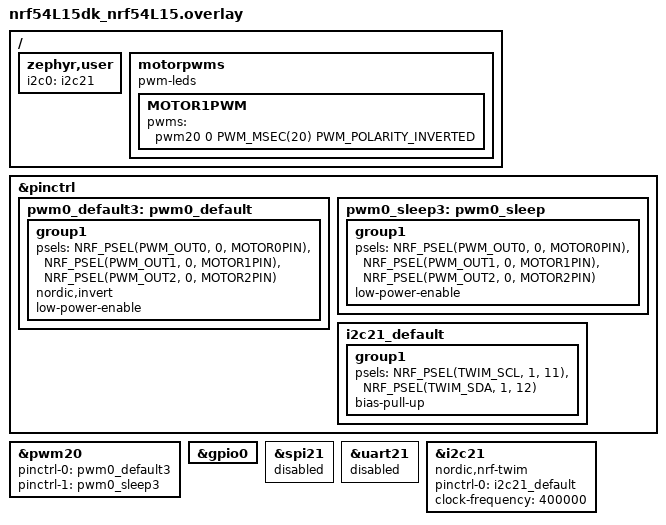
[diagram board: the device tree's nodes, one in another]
// To get started, press Ctrl+Space to bring up the completion menu and view the available nodes.

// You can also use the buttons in the sidebar to perform actions on nodes.
// Actions currently available include:

// * Enabling / disabling the node
// * Adding the bus to a bus
// * Removing the node
// * Connecting ADC channels

// For more help, browse the DeviceTree documentation at https://docs.zephyrproject.org/latest/guides/dts/index.html
// You can also visit the nRF DeviceTree extension documentation at https://nrfconnect.github.io/vscode-nrf-connect/devicetree/nrfdevicetree.html
/* old notation: 
&pwm0 {
    status = "okay";
    ch1-pin = <15>;
    /delete-property/ ch1-inverted;
}; */

#define MOTOR0PIN 14
#define MOTOR1PIN 13
#define MOTOR2PIN 15
/{
      
         zephyr,user {
             i2c0 = <&i2c21>;
             
     };
/*    chosen {
		zephyr,entropy = &rng;
	};
*/
    motorpwms: motorpwms {
		compatible = "pwm-leds";
		MOTOR1PWM: MOTOR1PWM {
			pwms = <&pwm20 0 PWM_MSEC(20) PWM_POLARITY_INVERTED>;
		};
        
	};
};

&pinctrl {
    pwm0_default3: pwm0_default {
        group1 {
            psels = <NRF_PSEL(PWM_OUT0, 0, MOTOR0PIN)>,
                    <NRF_PSEL(PWM_OUT1, 0, MOTOR1PIN)>,
                    <NRF_PSEL(PWM_OUT2, 0, MOTOR2PIN)>;
            nordic,invert;
            low-power-enable;
        };
    };

    pwm0_sleep3: pwm0_sleep {
        group1 {
            psels = <NRF_PSEL(PWM_OUT0, 0, MOTOR0PIN)>,
                    <NRF_PSEL(PWM_OUT1, 0, MOTOR1PIN)>,
                    <NRF_PSEL(PWM_OUT2, 0, MOTOR2PIN)>;
            low-power-enable;
        };
    };
};


&pwm20 {   
    pinctrl-0 = < &pwm0_default3 >;
    pinctrl-1 = < &pwm0_sleep3 >;
    pinctrl-names = "default", "sleep";
    status = "okay";
};

&gpio0 {
    status = "okay";
};

&spi21 { status = "disabled"; };
&uart21 { status = "disabled"; };


&i2c21 {    
    status = "okay";
    compatible = "nordic,nrf-twim";
    pinctrl-0 = <&i2c21_default>;
    pinctrl-names = "default";
    clock-frequency = <400000>;
   
};

&pinctrl {
    i2c21_default: i2c21_default {
        group1 {
            psels = <NRF_PSEL(TWIM_SCL, 1, 11)>, <NRF_PSEL(TWIM_SDA, 1, 12)>;
            bias-pull-up;
        };
    };
};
